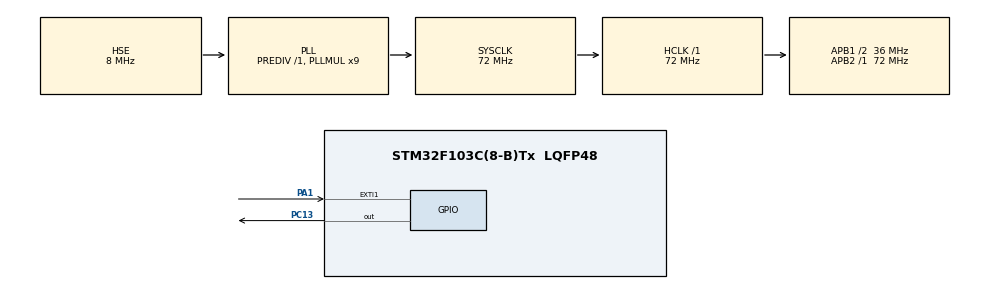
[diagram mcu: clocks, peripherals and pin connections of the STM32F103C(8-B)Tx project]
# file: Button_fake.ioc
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Mcu.Family=STM32F1
Mcu.Name=STM32F103C(8-B)Tx
Mcu.Package=LQFP48
NVIC.EXTI1_IRQn=true\:0\:0\:false\:false\:true\:true\:true
NVIC.PriorityGroup=NVIC_PRIORITYGROUP_4
PA1.GPIO_PuPd=GPIO_PULLDOWN
PA1.Signal=GPXTI1
PA13.Mode=Serial_Wire
PA13.Signal=SYS_JTMS-SWDIO
PA14.Mode=Serial_Wire
PA14.Signal=SYS_JTCK-SWCLK
PC13-TAMPER-RTC.GPIO_Speed=GPIO_SPEED_FREQ_MEDIUM
PC13-TAMPER-RTC.Signal=GPIO_Output
PD0-OSC_IN.Mode=HSE-External-Oscillator
PD0-OSC_IN.Signal=RCC_OSC_IN
PD1-OSC_OUT.Mode=HSE-External-Oscillator
PD1-OSC_OUT.Signal=RCC_OSC_OUT
ProjectManager.HeapSize=0x200
ProjectManager.StackSize=0x400
ProjectManager.TargetToolchain=MDK-ARM V5.27
RCC.AHBFreq_Value=72000000
RCC.APB1CLKDivider=RCC_HCLK_DIV2
RCC.APB1Freq_Value=36000000
RCC.APB1TimFreq_Value=72000000
RCC.APB2Freq_Value=72000000
RCC.APB2TimFreq_Value=72000000
RCC.HCLKFreq_Value=72000000
RCC.PLLMUL=RCC_PLL_MUL9
RCC.PLLSourceVirtual=RCC_PLLSOURCE_HSE
RCC.SYSCLKFreq_VALUE=72000000
RCC.SYSCLKSource=RCC_SYSCLKSOURCE_PLLCLK
RCC.USBFreq_Value=72000000
board=custom

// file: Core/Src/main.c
/* USER CODE BEGIN Header */
/**
  ******************************************************************************
  * @file           : main.c
  * @brief          : Main program body
  ******************************************************************************
  * @attention
  *
  * <h2><center>&copy; Copyright (c) 2021 STMicroelectronics.
  * All rights reserved.</center></h2>
  *
  * This software component is licensed by ST under BSD 3-Clause license,
  * the "License"; You may not use this file except in compliance with the
  * License. You may obtain a copy of the License at:
  *                        opensource.org/licenses/BSD-3-Clause
  *
  ******************************************************************************
  */
/* USER CODE END Header */
#include "main.h"

/* USER CODE BEGIN PM */

typedef struct
{
	GPIO_TypeDef *port;
	uint8_t event;
	uint16_t pin;
	uint32_t timeout;
	uint32_t time_press;
	void(*callback)(void);
}button;

void callback_blink(void)
{
	HAL_GPIO_TogglePin(GPIOC, GPIO_PIN_13);
}

button button_a = {
	.port = GPIOA,
	.pin = GPIO_PIN_1,
	.timeout = 1000,
	.callback = callback_blink,
};

/* USER CODE END PM */

void SystemClock_Config(void);
static void MX_GPIO_Init(void);

/* USER CODE BEGIN 0 */

void button_func(button *p)
{
	if (p->event == 1)
	{
		if (HAL_GetTick() - p->time_press > p->timeout)
		{
			if (HAL_GPIO_ReadPin(p->port, p->pin))
			{
				p->callback();
				p->event = 0;
			}
		}
	}
}

/* USER CODE END 0 */

int main(void)
{

  /* MCU Configuration--------------------------------------------------------*/

  /* Reset of all peripherals, Initializes the Flash interface and the Systick. */
  HAL_Init();

  /* Configure the system clock */
  SystemClock_Config();

  /* Initialize all configured peripherals */
  MX_GPIO_Init();
  /* USER CODE BEGIN 2 */
	HAL_GPIO_WritePin(GPIOC, GPIO_PIN_13, GPIO_PIN_SET);
  /* USER CODE END 2 */

  /* Infinite loop */
  while (1)
  {

    /* USER CODE BEGIN 3 */
		button_func(&button_a);
  }
  /* USER CODE END 3 */
}

void SystemClock_Config(void)
{
  RCC_OscInitTypeDef RCC_OscInitStruct = {0};
  RCC_ClkInitTypeDef RCC_ClkInitStruct = {0};

  /** Initializes the RCC Oscillators according to the specified parameters
  * in the RCC_OscInitTypeDef structure.
  */
  RCC_OscInitStruct.OscillatorType = RCC_OSCILLATORTYPE_HSE;
  RCC_OscInitStruct.HSEState = RCC_HSE_ON;
  RCC_OscInitStruct.HSEPredivValue = RCC_HSE_PREDIV_DIV1;
  RCC_OscInitStruct.HSIState = RCC_HSI_ON;
  RCC_OscInitStruct.PLL.PLLState = RCC_PLL_ON;
  RCC_OscInitStruct.PLL.PLLSource = RCC_PLLSOURCE_HSE;
  RCC_OscInitStruct.PLL.PLLMUL = RCC_PLL_MUL9;
  if (HAL_RCC_OscConfig(&RCC_OscInitStruct) != HAL_OK)
  {
    Error_Handler();
  }
  /** Initializes the CPU, AHB and APB buses clocks
  */
  RCC_ClkInitStruct.ClockType = RCC_CLOCKTYPE_HCLK|RCC_CLOCKTYPE_SYSCLK
                              |RCC_CLOCKTYPE_PCLK1|RCC_CLOCKTYPE_PCLK2;
  RCC_ClkInitStruct.SYSCLKSource = RCC_SYSCLKSOURCE_PLLCLK;
  RCC_ClkInitStruct.AHBCLKDivider = RCC_SYSCLK_DIV1;
  RCC_ClkInitStruct.APB1CLKDivider = RCC_HCLK_DIV2;
  RCC_ClkInitStruct.APB2CLKDivider = RCC_HCLK_DIV1;

  if (HAL_RCC_ClockConfig(&RCC_ClkInitStruct, FLASH_LATENCY_2) != HAL_OK)
  {
    Error_Handler();
  }
}

static void MX_GPIO_Init(void)
{
  GPIO_InitTypeDef GPIO_InitStruct = {0};

  /* GPIO Ports Clock Enable */
  __HAL_RCC_GPIOC_CLK_ENABLE();
  __HAL_RCC_GPIOD_CLK_ENABLE();
  __HAL_RCC_GPIOA_CLK_ENABLE();

  /*Configure GPIO pin Output Level */
  HAL_GPIO_WritePin(GPIOC, GPIO_PIN_13, GPIO_PIN_RESET);

  /*Configure GPIO pin : PC13 */
  GPIO_InitStruct.Pin = GPIO_PIN_13;
  GPIO_InitStruct.Mode = GPIO_MODE_OUTPUT_PP;
  GPIO_InitStruct.Pull = GPIO_NOPULL;
  GPIO_InitStruct.Speed = GPIO_SPEED_FREQ_MEDIUM;
  HAL_GPIO_Init(GPIOC, &GPIO_InitStruct);

  /*Configure GPIO pin : PA1 */
  GPIO_InitStruct.Pin = GPIO_PIN_1;
  GPIO_InitStruct.Mode = GPIO_MODE_IT_RISING;
  GPIO_InitStruct.Pull = GPIO_PULLDOWN;
  HAL_GPIO_Init(GPIOA, &GPIO_InitStruct);

  /* EXTI interrupt init*/
  HAL_NVIC_SetPriority(EXTI1_IRQn, 0, 0);
  HAL_NVIC_EnableIRQ(EXTI1_IRQn);

}

/* USER CODE BEGIN 4 */

void HAL_GPIO_EXTI_Callback(uint16_t GPIO_Pin)
{
	button_a.event = 1;
	button_a.time_press = HAL_GetTick();
}

/* USER CODE END 4 */

void Error_Handler(void)
{
  __disable_irq();
  while (1)
  {
  }
}

/************************ (C) COPYRIGHT STMicroelectronics *****END OF FILE****/
